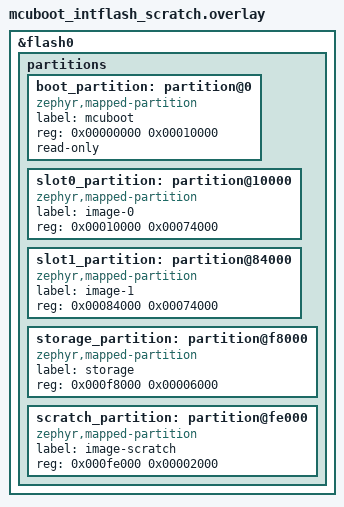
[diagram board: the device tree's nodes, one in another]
/*
 * SPDX-FileCopyrightText: Copyright (c) 2026 Nuvoton Technology Corporation
 * SPDX-License-Identifier: Apache-2.0
 */

/delete-node/ &slot0_partition;
/delete-node/ &slot1_partition;
/delete-node/ &storage_partition;

&flash0 {
	partitions {
		boot_partition: partition@0 {
			compatible = "zephyr,mapped-partition";
			label = "mcuboot";
			reg = <0x00000000 0x00010000>;
			read-only;
		};

		slot0_partition: partition@10000 {
			compatible = "zephyr,mapped-partition";
			label = "image-0";
			reg = <0x00010000 0x00074000>;
		};

		slot1_partition: partition@84000 {
			compatible = "zephyr,mapped-partition";
			label = "image-1";
			reg = <0x00084000 0x00074000>;
		};

		storage_partition: partition@f8000 {
			compatible = "zephyr,mapped-partition";
			label = "storage";
			reg = <0x000f8000 0x00006000>;
		};

		scratch_partition: partition@fe000 {
			compatible = "zephyr,mapped-partition";
			label = "image-scratch";
			reg = <0x000fe000 0x00002000>;
		};
	};
};
